# STM32F40x register map
File version: 1.5
Registers are 32-bit, read-write, reset 0x0 unless marked. A register's access mark holds for its fields unless they carry their own. Offsets are from the block's base; [hi:lo] are bit positions.

## Ethernet_PTP（以太网_PTP_精确时间协议） — 以太网 PTP 精确时间协议（best-effort） | Ethernet: Precision time protocol
Base 0x40028700
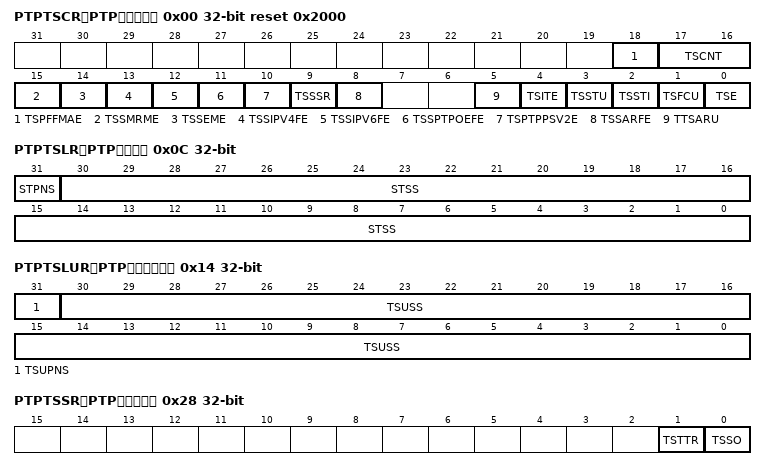
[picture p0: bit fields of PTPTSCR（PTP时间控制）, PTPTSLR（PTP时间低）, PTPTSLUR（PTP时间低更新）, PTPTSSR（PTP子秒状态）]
0x00 PTPTSCR（PTP时间控制） reset 0x2000 — PTP 时间戳控制 | Ethernet PTP time stamp control register
  [18] TSPFFMAE, [17:16] TSCNT, [15] TSSMRME, [14] TSSEME, [13] TSSIPV4FE, [12] TSSIPV6FE, [11] TSSPTPOEFE, [10] TSPTPPSV2E, [9] TSSSR, [8] TSSARFE, [5] TTSARU, [4] TSITE, [3] TSSTU, [2] TSSTI, [1] TSFCU, [0] TSE
0x04 PTPSSIR（PTP子秒增量） — PTP 子秒增量 | Ethernet PTP subsecond increment register
  [7:0] STSSI
0x08 PTPTSHR（PTP时间高） ro — PTP 时间戳高 | Ethernet PTP time stamp high register
  [31:0] STS
0x0C PTPTSLR（PTP时间低） ro — PTP 时间戳低 | Ethernet PTP time stamp low register
  [31] STPNS, [30:0] STSS
0x10 PTPTSHUR（PTP时间高更新） — PTP 时间高更新 | Ethernet PTP time stamp high update register
  [31:0] TSUS
0x14 PTPTSLUR（PTP时间低更新） — PTP 时间低更新 | Ethernet PTP time stamp low update register
  [31] TSUPNS, [30:0] TSUSS
0x18 PTPTSAR（PTP时间戳加） — PTP 时间戳加法 | Ethernet PTP time stamp addend register
  [31:0] TSA
0x1C PTPTTHR（PTP目标时间高） — PTP 目标时间高 | Ethernet PTP target time high register
  [31:0] TTSH — 0
0x20 PTPTTLR（PTP目标时间低） — PTP 目标时间低 | Ethernet PTP target time low register
  [31:0] TTSL
0x28 PTPTSSR（PTP子秒状态） ro — PTP 子秒状态 | Ethernet PTP time stamp status register
  [1] TSTTR, [0] TSSO
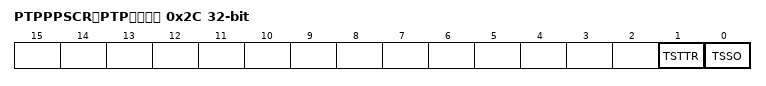
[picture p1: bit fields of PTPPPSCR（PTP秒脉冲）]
0x2C PTPPPSCR（PTP秒脉冲） ro — PTP 秒脉冲控制 | Ethernet PTP PPS control register
  [1] TSTTR, [0] TSSO

## Ethernet_DMA（以太网_DMA_控制器） — 以太网 DMA 控制器（best-effort） | Ethernet: DMA controller operation
Base 0x40029000
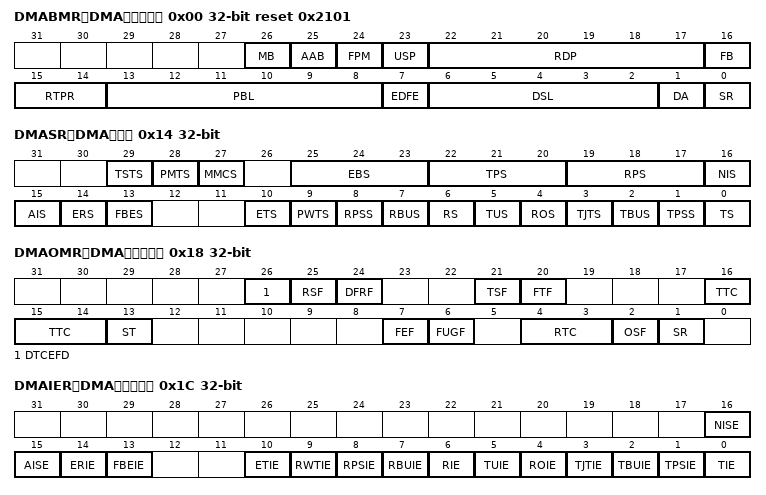
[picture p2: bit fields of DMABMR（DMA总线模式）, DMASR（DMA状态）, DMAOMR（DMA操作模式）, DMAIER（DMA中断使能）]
0x00 DMABMR（DMA总线模式） reset 0x2101 — DMA 总线模式 | Ethernet DMA bus mode register
  [26] MB, [25] AAB, [24] FPM, [23] USP, [22:17] RDP, [16] FB, [15:14] RTPR, [13:8] PBL, [7] EDFE, [6:2] DSL, [1] DA, [0] SR
0x04 DMATPDR（DMA当前发送） — DMA 当前发送指针 | Ethernet DMA transmit poll demand register
  [31:0] TPD
0x08 DMARPDR（DMA当前接收） — DMA 当前接收指针 | EHERNET DMA receive poll demand register
  [31:0] RPD
0x0C DMARDLAR（DMA接收描述符） — DMA 接收描述符列表地址 | Ethernet DMA receive descriptor list address register
  [31:0] SRL
0x10 DMATDLAR（DMA发送描述符） — DMA 发送描述符列表地址 | Ethernet DMA transmit descriptor list address register
  [31:0] STL
0x14 DMASR（DMA状态） access per field — DMA 状态 | Ethernet DMA status register
  [29] TSTS ro, [28] PMTS ro, [27] MMCS ro, [25:23] EBS ro, [22:20] TPS ro, [19:17] RPS ro, [16] NIS rw, [15] AIS rw, [14] ERS rw, [13] FBES rw, [10] ETS rw, [9] PWTS rw, [8] RPSS rw, [7] RBUS rw, [6] RS rw, [5] TUS rw, [4] ROS rw, [3] TJTS rw, [2] TBUS rw, [1] TPSS rw, [0] TS rw
0x18 DMAOMR（DMA操作模式） — DMA 操作模式 | Ethernet DMA operation mode register
  [26] DTCEFD, [25] RSF, [24] DFRF, [21] TSF, [20] FTF, [16:14] TTC, [13] ST, [7] FEF, [6] FUGF, [4:3] RTC, [2] OSF, [1] SR
0x1C DMAIER（DMA中断使能） — DMA 中断使能 | Ethernet DMA interrupt enable register
  [16] NISE, [15] AISE, [14] ERIE, [13] FBEIE, [10] ETIE, [9] RWTIE, [8] RPSIE, [7] RBUIE, [6] RIE, [5] TUIE, [4] ROIE, [3] TJTIE, [2] TBUIE, [1] TPSIE, [0] TIE
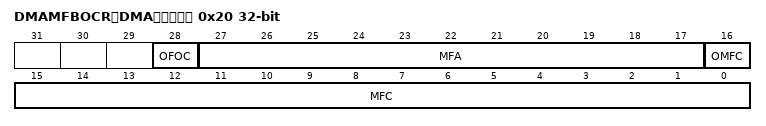
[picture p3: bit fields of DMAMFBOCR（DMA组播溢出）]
0x20 DMAMFBOCR（DMA组播溢出） — DMA 组播帧溢出计数 | Ethernet DMA missed frame and buffer overflow counter register
  [28] OFOC, [27:17] MFA, [16] OMFC, [15:0] MFC
0x24 DMARSWTR（DMA接收状态写） — DMA 接收状态写 | Ethernet DMA receive status watchdog timer register
  [7:0] RSWTC
0x48 DMACHTDR（DMA当前主机发送） ro — DMA 当前主机发送描述符 | Ethernet DMA current host transmit descriptor register
  [31:0] HTDAP
0x4C DMACHRDR（DMA当前主机接收） ro — DMA 当前主机接收描述符 | Ethernet DMA current host receive descriptor register
  [31:0] HRDAP
0x50 DMACHTBAR（DMA主机发送底） ro — DMA 主机发送描述符底 | Ethernet DMA current host transmit buffer address register
  [31:0] HTBAP
0x54 DMACHRBAR（DMA主机接收底） ro — DMA 主机接收描述符底 | Ethernet DMA current host receive buffer address register
  [31:0] HRBAP

## CRC（循环冗余校验） — CRC 计算单元：数据校验 | Cryptographic processor
Base 0x40023000
0x00 DR（数据） reset 0xFFFFFFFF — 数据：CRC 计算数据/结果 | Data register
  [31:0] DR — Data Register
0x04 IDR（独立数据） — 独立数据：用户数据（断电保留） | Independent Data register
  [7:0] IDR — Independent Data register
0x08 CR（控制） wo — 控制：CRC 复位 | Control register
  [0] CR — Control regidter
